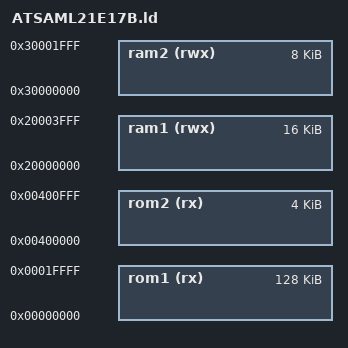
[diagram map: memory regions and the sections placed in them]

MEMORY
{
  rom1 (rx) : ORIGIN = 0x00000000, LENGTH = 0x20000
  rom2 (rx) : ORIGIN = 0x00400000, LENGTH = 0x1000
  ram1 (rwx) : ORIGIN = 0x20000000, LENGTH = 0x4000
  ram2 (rwx) : ORIGIN = 0x30000000, LENGTH = 0x2000
}

